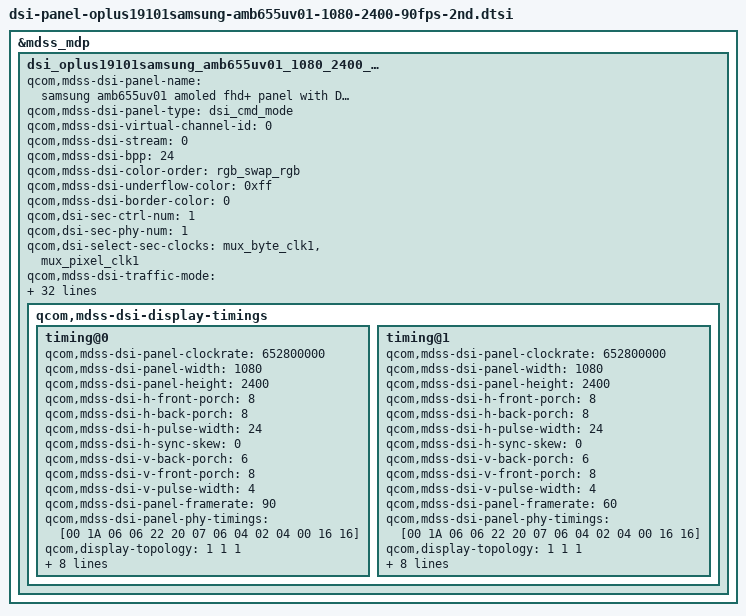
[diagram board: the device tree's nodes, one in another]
&mdss_mdp {
	dsi_oplus19101samsung_amb655uv01_1080_2400_cmd_2nd: qcom,mdss_dsi_oplus19101samsung_amb655uv01_1080_2400_cmd_2nd {
		qcom,mdss-dsi-panel-name =
		  "samsung amb655uv01 amoled fhd+ panel with DSC 2nd";
		qcom,mdss-dsi-panel-type = "dsi_cmd_mode";
		qcom,mdss-dsi-virtual-channel-id = <0>;
		qcom,mdss-dsi-stream = <0>;
		qcom,mdss-dsi-bpp = <24>;
		qcom,mdss-dsi-color-order = "rgb_swap_rgb";
		qcom,mdss-dsi-underflow-color = <0xff>;
		qcom,mdss-dsi-border-color = <0>;

		qcom,dsi-sec-ctrl-num = <1>;
		qcom,dsi-sec-phy-num = <1>;
		qcom,dsi-select-sec-clocks = "mux_byte_clk1", "mux_pixel_clk1";

		qcom,mdss-dsi-traffic-mode = "non_burst_sync_event";
		qcom,mdss-dsi-lane-map = "lane_map_0123";
		qcom,mdss-dsi-bllp-eof-power-mode;
		qcom,mdss-dsi-bllp-power-mode;
		qcom,mdss-dsi-lane-0-state;
		qcom,mdss-dsi-lane-1-state;
		qcom,mdss-dsi-lane-2-state;
		qcom,mdss-dsi-lane-3-state;
		qcom,mdss-dsi-dma-trigger = "trigger_sw";
		qcom,mdss-dsi-mdp-trigger = "none";
		qcom,mdss-dsi-reset-sequence = <1 10>, <0 10>, <1 10>;
		qcom,mdss-dsi-te-pin-select = <1>;
		qcom,mdss-dsi-te-dcs-command = <1>;
		qcom,mdss-dsi-te-using-te-pin;
		qcom,mdss-dsi-lp11-init;
		qcom,mdss-dsi-wr-mem-start = <0x2c>;
		qcom,mdss-dsi-wr-mem-continue = <0x3c>;
		qcom,mdss-dsi-panel-hdr-enabled;
		qcom,mdss-dsi-panel-hdr-color-primaries = <15000 15500 34000
			16000 13250 34500 7500 3000>;
		qcom,mdss-dsi-panel-peak-brightness = <4300000>;
		qcom,mdss-dsi-panel-blackness-level = <1023>;

		qcom,mdss-dsi-display-timings {
			timing@0{
				qcom,mdss-dsi-panel-clockrate = <652800000>;
				qcom,mdss-dsi-panel-width = <1080>;
				qcom,mdss-dsi-panel-height = <2400>;
				qcom,mdss-dsi-h-front-porch = <8>;
				qcom,mdss-dsi-h-back-porch = <8>;
				qcom,mdss-dsi-h-pulse-width = <24>;
				qcom,mdss-dsi-h-sync-skew = <0>;
				qcom,mdss-dsi-v-back-porch = <6>;
				qcom,mdss-dsi-v-front-porch = <8>;
				qcom,mdss-dsi-v-pulse-width = <4>;
				qcom,mdss-dsi-panel-framerate = <90>;
				qcom,mdss-dsi-panel-phy-timings = [00 22 05 09 25 23 09 09 06 03 04 00];
				qcom,display-topology = <1 1 1>;
				qcom,default-topology-index = <0>;
				qcom,compression-mode = "dsc";
				qcom,mdss-dsc-slice-height = <48>;
				qcom,mdss-dsc-slice-width = <540>;
				qcom,mdss-dsc-slice-per-pkt = <2>;
				qcom,mdss-dsc-bit-per-component = <8>;
				qcom,mdss-dsc-bit-per-pixel = <8>;
				qcom,mdss-dsc-block-prediction-enable;
			};

			timing@1{
				qcom,mdss-dsi-panel-clockrate = <652800000>;
				qcom,mdss-dsi-panel-width = <1080>;
				qcom,mdss-dsi-panel-height = <2400>;
				qcom,mdss-dsi-h-front-porch = <8>;
				qcom,mdss-dsi-h-back-porch = <8>;
				qcom,mdss-dsi-h-pulse-width = <24>;
				qcom,mdss-dsi-h-sync-skew = <0>;
				qcom,mdss-dsi-v-back-porch = <6>;
				qcom,mdss-dsi-v-front-porch = <8>;
				qcom,mdss-dsi-v-pulse-width = <4>;
				qcom,mdss-dsi-panel-framerate = <60>;
				qcom,mdss-dsi-panel-phy-timings = [00 22 05 09 25 23 09 09 06 03 04 00];
				qcom,display-topology = <1 1 1>;
				qcom,default-topology-index = <0>;
				qcom,compression-mode = "dsc";
				qcom,mdss-dsc-slice-height = <48>;
				qcom,mdss-dsc-slice-width = <540>;
				qcom,mdss-dsc-slice-per-pkt = <2>;
				qcom,mdss-dsc-bit-per-component = <8>;
				qcom,mdss-dsc-bit-per-pixel = <8>;
				qcom,mdss-dsc-block-prediction-enable;
			};

		};
	};
};

&dsi_oplus19101samsung_amb655uv01_1080_2400_cmd_2nd {
	qcom,panel-sec-supply-entries = <&dsi_panel_pwr_supply>;
	qcom,mdss-dsi-sec-bl-pmic-control-type = "bl_ctrl_external";
	qcom,mdss-dsi-bl-min-level = <1>;
	qcom,mdss-dsi-bl-max-level = <1023>;
	qcom,mdss-brightness-max-level = <1023>;
	qcom,platform-te-gpio = <&tlmm 11 0>;
	//qcom,ulps-enabled;
	qcom,mdss-dsi-t-clk-post = <0x0E>;
	qcom,mdss-dsi-t-clk-pre = <0x35>;
	qcom,mdss-dsi-display-timings {
		timing@0{
			qcom,mdss-dsi-panel-phy-timings = [00 1A 06 06 22 20 07
				06 04 02 04 00 16 16];

			qcom,display-topology = <1 1 1>;
			qcom,default-topology-index = <0>;
		};
		timing@1{
			qcom,mdss-dsi-panel-phy-timings = [00 1A 06 06 22 20 07
				06 04 02 04 00 16 16];

			qcom,display-topology = <1 1 1>;
			qcom,default-topology-index = <0>;
		};
	};
};
